# STM32G474xx register map
File version: 1.5
CPU: CM4 r0p1, little endian, MPU, FPU, 4 interrupt priority bits
Registers are 32-bit, read-write, reset 0x0 unless marked. A register's access mark holds for its fields unless they carry their own. Offsets are from the block's base; [hi:lo] are bit positions; {n}, {i} and the like mark numbered series.

## CRC — Cyclic redundancy check calculation unit
Base 0x40023000
0x00 DR reset 0xFFFFFFFF — Data register
  [31:0] DR — Data register bits
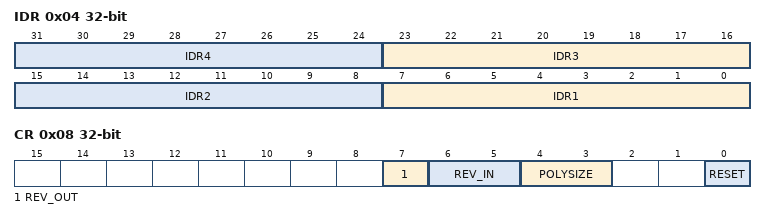
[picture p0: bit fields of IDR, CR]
0x04 IDR — Independent data register
  [8n-1:8n-8] IDR{n} (n=1..4) — General-purpose 8-bit data register bits
0x08 CR access per field — Control register
  [7] REV_OUT rw — Reverse output data
  [6:5] REV_IN rw — Reverse input data
  [4:3] POLYSIZE rw — Polynomial size
  [0] RESET wo — RESET bit
0x10 INIT reset 0xFFFFFFFF — Initial CRC value
  [31:0] CRC_INIT — Programmable initial CRC value
0x14 POL reset 0x4C11DB7 — polynomial
  [31:0] POL — Programmable polynomial

## IWDG — WinWATCHDOG
Base 0x40003000
0x00 KR wo — Key register
  [15:0] KEY — Key value (write only, read 0x0000)
0x04 PR — Prescaler register
  [2:0] PR — Prescaler divider
0x08 RLR reset 0xFFF — Reload register
  [11:0] RL — Watchdog counter reload value
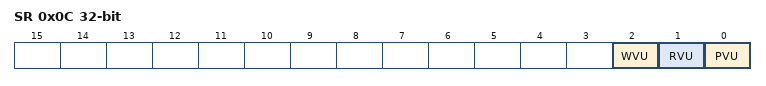
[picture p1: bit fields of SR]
0x0C SR ro — Status register
  [2] WVU — Watchdog counter window value update
  [1] RVU — Watchdog counter reload value update
  [0] PVU — Watchdog prescaler value update
0x10 WINR reset 0xFFF — Window register
  [11:0] WIN — Watchdog counter window value

## WWDG — System window watchdog
Base 0x40002C00
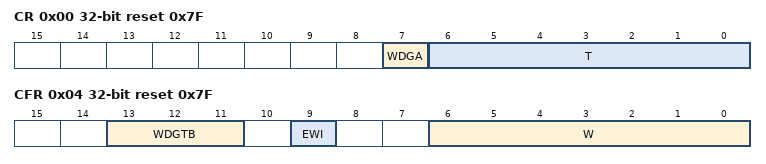
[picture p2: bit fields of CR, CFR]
0x00 CR reset 0x7F — Control register
  [7] WDGA — Activation bit
  [6:0] T — 7-bit counter (MSB to LSB)
0x04 CFR reset 0x7F — Configuration register
  [13:11] WDGTB — Timer base
  [9] EWI — Early wakeup interrupt
  [6:0] W — 7-bit window value
0x08 SR — Status register
  [0] EWIF — Early wakeup interrupt flag

## FLASH
Base 0x40022000
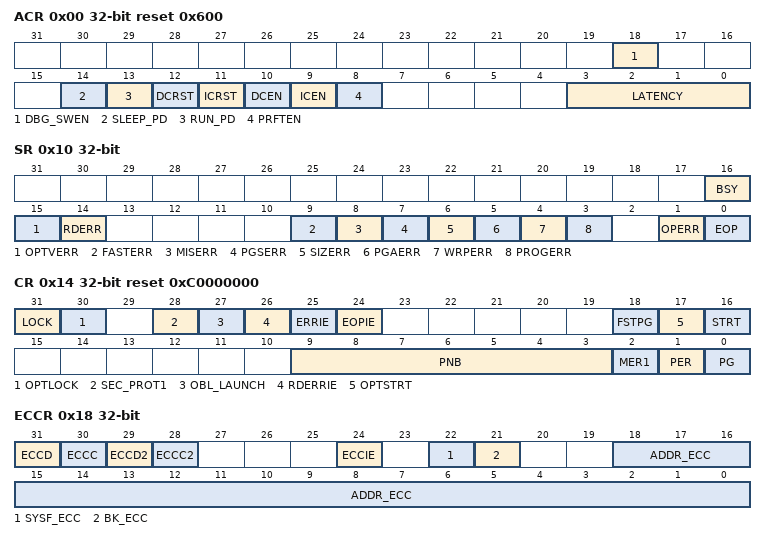
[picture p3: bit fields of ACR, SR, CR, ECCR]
0x00 ACR reset 0x600 — Access control register
  [18] DBG_SWEN — Debug software enable
  [14] SLEEP_PD — Flash Power-down mode during Low-power sleep mode
  [13] RUN_PD — Flash Power-down mode during Low-power run mode
  [12] DCRST — Data cache reset
  [11] ICRST — Instruction cache reset
  [10] DCEN — Data cache enable
  [9] ICEN — Instruction cache enable
  [8] PRFTEN — Prefetch enable
  [3:0] LATENCY
0x04 PDKEYR wo — Power down key register
  [31:0] PDKEYR — RUN_PD in FLASH_ACR key
0x08 KEYR wo — Flash key register
0x0C OPTKEYR wo — Option byte key register
  [31:0] OPTKEYR — Option byte key
0x10 SR access per field — Status register
  [16] BSY ro — Busy
  [15] OPTVERR rw — Option validity error
  [14] RDERR rw — PCROP read error
  [9] FASTERR rw — Fast programming error
  [8] MISERR rw — Fast programming data miss error
  [7] PGSERR rw — Programming sequence error
  [6] SIZERR rw — Size error
  [5] PGAERR rw — Programming alignment error
  [4] WRPERR rw — Write protected error
  [3] PROGERR rw — Programming error
  [1] OPERR rw — Operation error
  [0] EOP rw — End of operation
0x14 CR reset 0xC0000000 — Flash control register
  [31] LOCK — FLASH_CR Lock
  [30] OPTLOCK — Options Lock
  [28] SEC_PROT1
  [27] OBL_LAUNCH — Force the option byte loading
  [26] RDERRIE — PCROP read error interrupt enable
  [25] ERRIE — Error interrupt enable
  [24] EOPIE — End of operation interrupt enable
  [18] FSTPG — Fast programming
  [17] OPTSTRT — Options modification start
  [16] STRT — Start
  [9:3] PNB — Page number
  [2] MER1 — Bank 1 Mass erase
  [1] PER — Page erase
  [0] PG — Programming
0x18 ECCR access per field — Flash ECC register
  [31] ECCD rw — ECC detection
  [30] ECCC rw — ECC correction
  [29] ECCD2 rw — ECC2 detection
  [28] ECCC2 rw — ECC correction
  [24] ECCIE rw
  [22] SYSF_ECC ro
  [21] BK_ECC ro
  [18:0] ADDR_ECC ro — ECC fail address
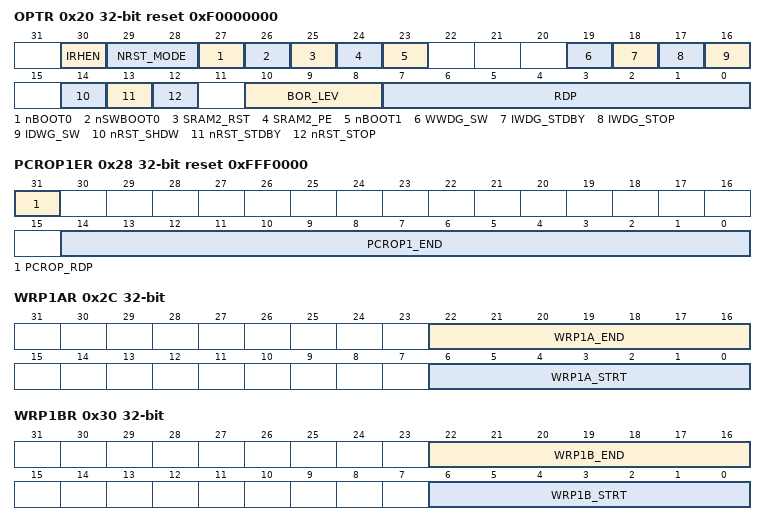
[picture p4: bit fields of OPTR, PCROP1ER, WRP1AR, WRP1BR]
0x20 OPTR reset 0xF0000000 — Flash option register
  [30] IRHEN
  [29:28] NRST_MODE
  [27] nBOOT0
  [26] nSWBOOT0
  [25] SRAM2_RST — SRAM2 Erase when system reset
  [24] SRAM2_PE — SRAM2 parity check enable
  [23] nBOOT1 — Boot configuration
  [19] WWDG_SW — Window watchdog selection
  [18] IWDG_STDBY — Independent watchdog counter freeze in Standby mode
  [17] IWDG_STOP — Independent watchdog counter freeze in Stop mode
  [16] IDWG_SW — Independent watchdog selection
  [14] nRST_SHDW
  [13] nRST_STDBY
  [12] nRST_STOP
  [10:8] BOR_LEV — BOR reset Level
  [7:0] RDP — Read protection level
0x24 PCROP1SR reset 0xFFFF0000 — Flash Bank 1 PCROP Start address register
  [14:0] PCROP1_STRT — Bank 1 PCROP area start offset
0x28 PCROP1ER reset 0xFFF0000 — Flash Bank 1 PCROP End address register
  [31] PCROP_RDP — PCROP area preserved when RDP level decreased
  [14:0] PCROP1_END — Bank 1 PCROP area end offset
0x2C WRP1AR — Flash Bank 1 WRP area A address register
  [22:16] WRP1A_END — Bank 1 WRP first area A end offset
  [6:0] WRP1A_STRT — Bank 1 WRP first area start offset
0x30 WRP1BR — Flash Bank 1 WRP area B address register
  [22:16] WRP1B_END — Bank 1 WRP second area B start offset
  [6:0] WRP1B_STRT — Bank 1 WRP second area B end offset
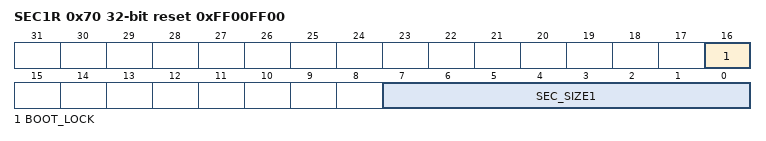
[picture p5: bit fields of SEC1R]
0x70 SEC1R reset 0xFF00FF00 — securable area bank1 register
  [16] BOOT_LOCK, [7:0] SEC_SIZE1
